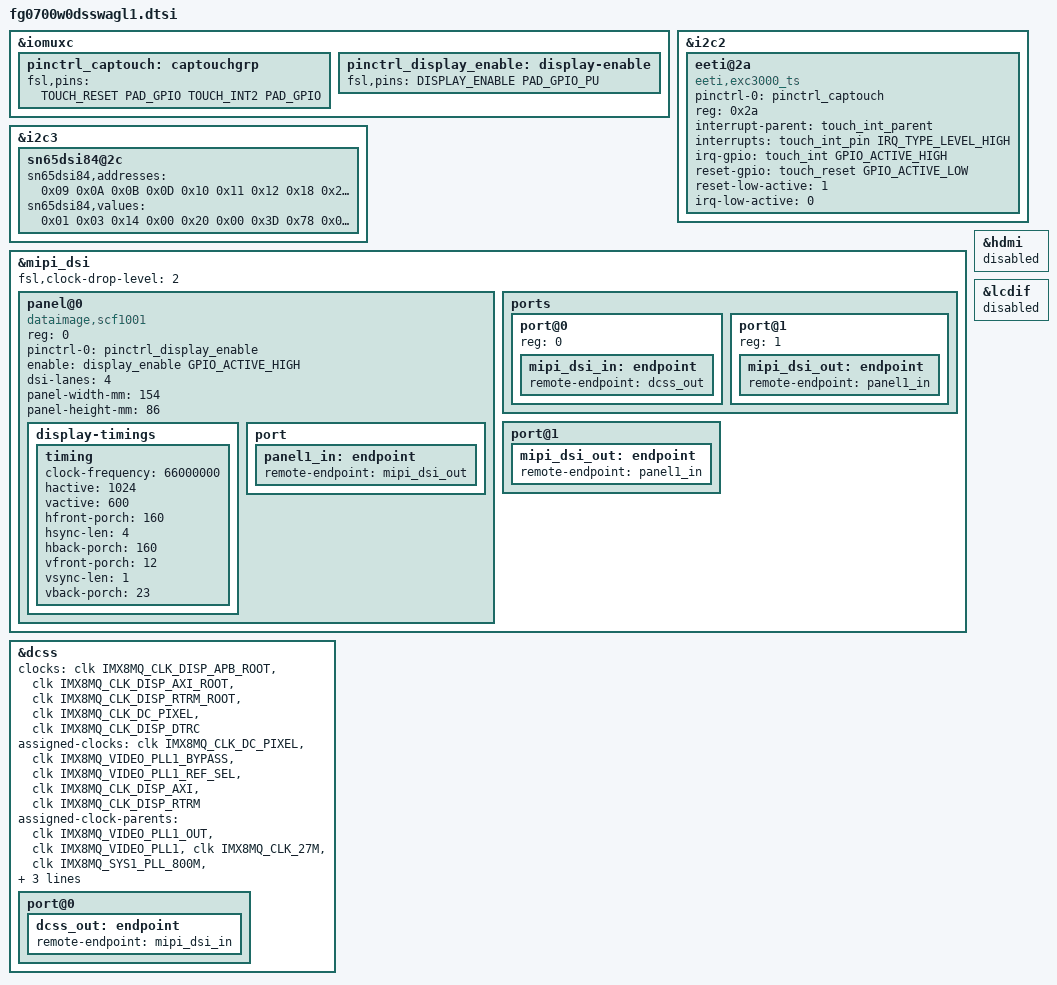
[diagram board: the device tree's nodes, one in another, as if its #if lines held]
/*
 * Copyright 2020 Keith & Koep GmbH
 *
 */

/*
Defines:
    TOUCH_USE_INT2  Set if alternate touch-interrupt should be used.

    TOUCH_INT      Defined in xxx_pinfunc.h. (SODIMM-pin: 45: pConXS)
    TOUCH_INT2     Defined in xxx_pinfunc.h. (SODIMM-pin: 55: i-PANT7, i-PAN T10)
    TOUCH_RESET    Defined in xxx_pinfunc.h. (SODIMM-pin: 75)
*/

&iomuxc {
	pinctrl_captouch: captouchgrp {
		fsl,pins = <                    
					 TOUCH_RESET		PAD_GPIO /* WAKE */
#if defined(TOUCH_USE_INT2) && (TOUCH_USE_INT2==1)
					 TOUCH_INT2 		PAD_GPIO /* IRQ */
#else
					 TOUCH_INT  		PAD_GPIO /* IRQ */
#endif
			   	>;
	};
		
	pinctrl_display_enable: display-enable 	{
		fsl,pins = < DISPLAY_ENABLE		PAD_GPIO_PU >; /* DISPLAY_ENABLE */
	};
};

&i2c2 {

	eeti@2a {
		compatible = "eeti,exc3000_ts"; // out of tree driver
		//compatible = "eeti,exc3000";  // kernel driver
		pinctrl-names = "default";
		pinctrl-0 = <&pinctrl_captouch>;
		reg = <0x2a>;
		interrupt-parent = <touch_int_parent>;
		interrupts = <touch_int_pin IRQ_TYPE_LEVEL_HIGH>;
        irq-gpio = <touch_int GPIO_ACTIVE_HIGH>;

        // Reset pol unklar, da Reset gar nicht funktioniert
        reset-gpio = <touch_reset GPIO_ACTIVE_LOW>;
        reset-low-active = <1>;
        irq-low-active = <0>;

		status = "okay";
	};
};

&i2c3 {
	sn65dsi84@2c {
		status = "ok";
			sn65dsi84,addresses = <	
						0x09 0x0A 0x0B 0x0D 0x10 0x11 0x12
						0x18 0x20 0x21 0x24 0x25 0x28 0x29
						0x2C 0x2D 0x30 0x31 0x34 0x36 0x38 
						0x3A 0x3C 0x0D>;
			sn65dsi84,values =  <
						0x01 0x03 0x14 0x00 0x20 0x00 0x3D
						0x78 0x00 0x04 0x58 0x02 0x20 0x00
						0x04 0x00 0x01 0x00 0xA0 0x17 0xA0
						0x0C 0x00 0x01>;
	};
};

&mipi_dsi {
	status              = "okay";
	panel@0 {
		status          = "okay";
		compatible      = "dataimage,scf1001";
		reg             = <0>;
		pinctrl-0       = <&pinctrl_display_enable>;
		enable          = <display_enable GPIO_ACTIVE_HIGH>;
		dsi-lanes       = <4>;
		panel-width-mm = <154>;
		panel-height-mm = <86>;

		display-timings {
			timing {
				clock-frequency = <66000000>;
				hactive = <1024>;
				vactive = <600>;
				hfront-porch = <160>;
				hsync-len = <4>;
				hback-porch = <160>;
				vfront-porch = <12>;
				vsync-len = <1>;
				vback-porch = <23>;
			};
		};

		port {
			panel1_in: endpoint {
				remote-endpoint = <&mipi_dsi_out>;
			};
		};
	};
};

/************************************************************************/
#if defined (__DTS_TRIZEPS8_PINFUNC_H)
&hdmi {
	status = "disabled";
};

&lcdif {
	status = "disabled";
};

&dcss {
	status = "okay";

	clocks = <&clk IMX8MQ_CLK_DISP_APB_ROOT>,
		 <&clk IMX8MQ_CLK_DISP_AXI_ROOT>,
		 <&clk IMX8MQ_CLK_DISP_RTRM_ROOT>,
		 <&clk IMX8MQ_CLK_DC_PIXEL>,
		 <&clk IMX8MQ_CLK_DISP_DTRC>;
	clock-names = "apb", "axi", "rtrm", "pix", "dtrc";
	assigned-clocks = <&clk IMX8MQ_CLK_DC_PIXEL>,
					  <&clk IMX8MQ_VIDEO_PLL1_BYPASS>,
					  <&clk IMX8MQ_VIDEO_PLL1_REF_SEL>,
					  <&clk IMX8MQ_CLK_DISP_AXI>,
					  <&clk IMX8MQ_CLK_DISP_RTRM>;
	assigned-clock-parents = <&clk IMX8MQ_VIDEO_PLL1_OUT>,
							 <&clk IMX8MQ_VIDEO_PLL1>,
							 <&clk IMX8MQ_CLK_27M>,
							 <&clk IMX8MQ_SYS1_PLL_800M>,
							 <&clk IMX8MQ_SYS1_PLL_800M>;
	assigned-clock-rates = <600000000>, <0>, <0>,
						   <800000000>,
						   <400000000>;

	port@0 {
		dcss_out: endpoint {
			remote-endpoint = <&mipi_dsi_in>;
		};
	};
};

&mipi_dsi {
    fsl,clock-drop-level = <2>;
	ports {
		#address-cells = <1>;
		#size-cells = <0>;

		port@0 {
			reg = <0>;
			mipi_dsi_in: endpoint {
				remote-endpoint = <&dcss_out>;
			};
		};

		port@1 {
			reg = <1>;
			mipi_dsi_out: endpoint {
				remote-endpoint = <&panel1_in>;
			};
		};
	};
};
#endif
/************************************************************************/
#if defined (__DTS_IMX8MM_PINFUNC_H) || defined (__DTS_IMX8MN_PINFUNC_H)
&mipi_dsi {
	port@1 {
		mipi_dsi_out: endpoint {
			remote-endpoint = <&panel1_in>;
		};
	};
};
#endif
/************************************************************************/

